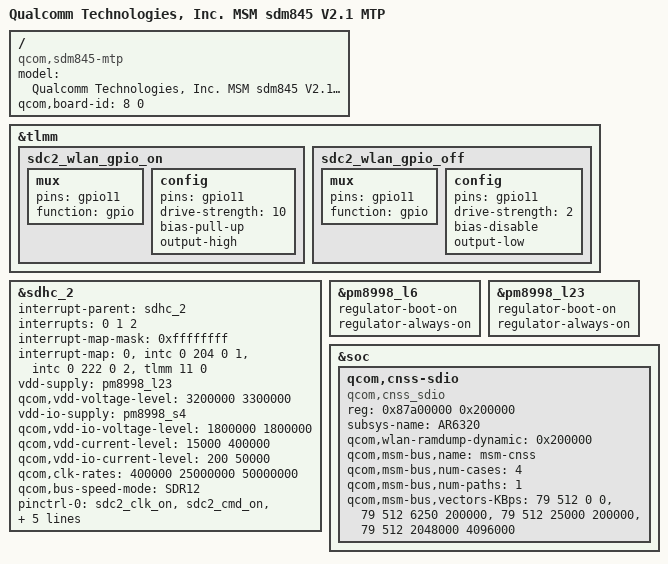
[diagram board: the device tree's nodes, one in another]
/* Copyright (c) 2019-2020, The Linux Foundation. All rights reserved.
 *
 * This program is free software; you can redistribute it and/or modify
 * it under the terms of the GNU General Public License version 2 and
 * only version 2 as published by the Free Software Foundation.
 *
 * This program is distributed in the hope that it will be useful,
 * but WITHOUT ANY WARRANTY; without even the implied warranty of
 * MERCHANTABILITY or FITNESS FOR A PARTICULAR PURPOSE.  See the
 * GNU General Public License for more details.
 */


/dts-v1/;

#include "sdm845-v2.1.dtsi"
#include "sdm845-sde-display.dtsi"
#include "sdm845-mtp.dtsi"
#include "sdm845-audio-overlay.dtsi"

/ {
	model = "Qualcomm Technologies, Inc. MSM sdm845 V2.1 MTP";
	compatible = "qcom,sdm845-mtp", "qcom,sdm845", "qcom,mtp";
	qcom,board-id = <8 0>;
};

&tlmm {
	sdc2_wlan_gpio_on: sdc2_wlan_gpio_on {
		mux {
			pins = "gpio11";
			function = "gpio";
		};
		config {
			pins = "gpio11";
			drive-strength = <10>;
			bias-pull-up;
			output-high;
		};
	};

	sdc2_wlan_gpio_off: sdc2_wlan_gpio_off {
		mux {
			pins = "gpio11";
			function = "gpio";
		};
		config {
			pins = "gpio11";
			drive-strength = <2>;
			bias-disable;
			output-low;
		};
	};
};

&sdhc_2 {
	/delete-property/cd-gpios;
	#address-cells = <0>;
	interrupt-parent = <&sdhc_2>;
	interrupts = <0 1 2>;
	#interrupt-cells = <1>;
	interrupt-map-mask = <0xffffffff>;
	interrupt-map = <0 &intc 0 204 0
		1 &intc 0 222 0
		2 &tlmm 11 0>;
	interrupt-names = "hc_irq", "pwr_irq", "sdiowakeup_irq";

	vdd-supply = <&pm8998_l23>;
	qcom,vdd-voltage-level = <3200000 3300000>;
	vdd-io-supply = <&pm8998_s4>;
	qcom,vdd-io-voltage-level = <1800000 1800000>;
	qcom,vdd-current-level = <15000 400000>;
	qcom,vdd-io-current-level = <200 50000>;
	qcom,clk-rates = <400000 25000000 50000000>;
	qcom,bus-speed-mode = "SDR12";
	pinctrl-names = "active", "sleep";
	pinctrl-0 = <&sdc2_clk_on &sdc2_cmd_on &sdc2_data_on
			&sdc2_wlan_gpio_on>;
	pinctrl-1 = <&sdc2_clk_off &sdc2_cmd_off &sdc2_data_off
			&sdc2_wlan_gpio_off>;
	qcom,nonremovable;
	qcom,core_3_0v_support;
	status = "ok";
};

&pm8998_l6 {
	regulator-boot-on;
	regulator-always-on;
};

&pm8998_l23 {
	regulator-boot-on;
	regulator-always-on;
};

&soc {
	qcom,cnss-sdio {
		compatible = "qcom,cnss_sdio";
		reg = <0x87a00000 0x200000>;
		reg-names = "ramdump";
		subsys-name = "AR6320";
		qcom,wlan-ramdump-dynamic = <0x200000>;
		qcom,msm-bus,name = "msm-cnss";
		qcom,msm-bus,num-cases = <4>;
		qcom,msm-bus,num-paths = <1>;
		qcom,msm-bus,vectors-KBps =
				<79 512 0 0>,             /* No vote */
				<79 512 6250 200000>,     /* 50 Mbps */
				<79 512 25000 200000>,    /* 200 Mbps */
				<79 512 2048000 4096000>; /* MAX */
	};
};
